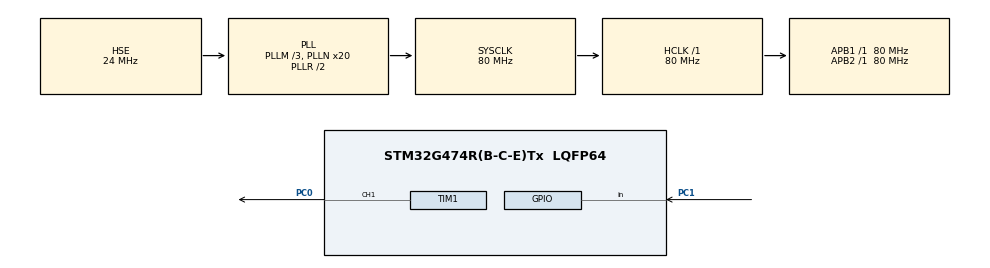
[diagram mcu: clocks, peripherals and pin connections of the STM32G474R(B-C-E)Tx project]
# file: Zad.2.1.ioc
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Dma.Request0=TIM1_CH1
Dma.TIM1_CH1.0.Direction=DMA_MEMORY_TO_PERIPH
Dma.TIM1_CH1.0.EventEnable=DISABLE
Dma.TIM1_CH1.0.Instance=DMA1_Channel1
Dma.TIM1_CH1.0.MemDataAlignment=DMA_MDATAALIGN_BYTE
Dma.TIM1_CH1.0.MemInc=DMA_MINC_ENABLE
Dma.TIM1_CH1.0.Mode=DMA_NORMAL
Dma.TIM1_CH1.0.PeriphDataAlignment=DMA_PDATAALIGN_HALFWORD
Dma.TIM1_CH1.0.PeriphInc=DMA_PINC_DISABLE
Dma.TIM1_CH1.0.Polarity=HAL_DMAMUX_REQ_GEN_RISING
Dma.TIM1_CH1.0.Priority=DMA_PRIORITY_LOW
Dma.TIM1_CH1.0.RequestNumber=1
Dma.TIM1_CH1.0.SignalID=NONE
Dma.TIM1_CH1.0.SyncEnable=DISABLE
Dma.TIM1_CH1.0.SyncPolarity=HAL_DMAMUX_SYNC_NO_EVENT
Dma.TIM1_CH1.0.SyncRequestNumber=1
Dma.TIM1_CH1.0.SyncSignalID=NONE
Mcu.Family=STM32G4
Mcu.Name=STM32G474R(B-C-E)Tx
Mcu.Package=LQFP64
NVIC.DMA1_Channel1_IRQn=true\:0\:0\:false\:false\:true\:false\:true\:true
NVIC.PriorityGroup=NVIC_PRIORITYGROUP_4
PC0.Signal=S_TIM1_CH1
PC1.GPIO_PuPd=GPIO_PULLUP
PC1.Signal=GPIO_Input
PF0-OSC_IN.Mode=HSE-External-Oscillator
PF0-OSC_IN.Signal=RCC_OSC_IN
PF1-OSC_OUT.Mode=HSE-External-Oscillator
PF1-OSC_OUT.Signal=RCC_OSC_OUT
ProjectManager.HeapSize=0x200
ProjectManager.StackSize=0x400
ProjectManager.TargetToolchain=CMake
RCC.ADC12Freq_Value=80000000
RCC.ADC345Freq_Value=80000000
RCC.AHBFreq_Value=80000000
RCC.APB1Freq_Value=80000000
RCC.APB1TimFreq_Value=80000000
RCC.APB2Freq_Value=80000000
RCC.APB2TimFreq_Value=80000000
RCC.CortexFreq_Value=80000000
RCC.EXTERNAL_CLOCK_VALUE=12288000
RCC.HCLKFreq_Value=80000000
RCC.HSE_VALUE=24000000
RCC.HSI48_VALUE=48000000
RCC.HSI_VALUE=16000000
RCC.LSE_VALUE=32768
RCC.PLLM=RCC_PLLM_DIV3
RCC.PLLN=20
RCC.PLLSourceVirtual=RCC_PLLSOURCE_HSE
RCC.SYSCLKFreq_VALUE=80000000
RCC.SYSCLKSource=RCC_SYSCLKSOURCE_PLLCLK
RCC.USBFreq_Value=80000000
RCC.VCOOutputFreq_Value=160000000
SH.S_TIM1_CH1.0=TIM1_CH1,PWM Generation1 CH1
TIM1.Channel-PWM\ Generation1\ CH1=TIM_CHANNEL_1
TIM1.PeriodNoDither=100-1
VP_SYS_VS_DBSignals.Mode=DisableDeadBatterySignals
VP_TIM1_VS_ClockSourceINT.Mode=Internal
board=custom

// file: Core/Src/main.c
/* USER CODE BEGIN Header */
/**
  ******************************************************************************
  * @file           : main.c
  * @brief          : Main program body
  ******************************************************************************
  * @attention
  *
  * Copyright (c) 2026 STMicroelectronics.
  * All rights reserved.
  *
  * This software is licensed under terms that can be found in the LICENSE file
  * in the root directory of this software component.
  * If no LICENSE file comes with this software, it is provided AS-IS.
  *
  ******************************************************************************
  */
/* USER CODE END Header */
#include "main.h"

/* USER CODE BEGIN Includes */
#include "driver-ws2812.h"
/* USER CODE END Includes */

/* USER CODE BEGIN PD */
#define BTN_GPIO 	 GPIOC
#define BTN_PIN  	 GPIO_PIN_1
#define BTN_DEBOUNCE 50 // in ms
/* USER CODE END PD */

TIM_HandleTypeDef htim1;
DMA_HandleTypeDef hdma_tim1_ch1;

void SystemClock_Config(void);
static void MX_GPIO_Init(void);
static void MX_DMA_Init(void);
static void MX_TIM1_Init(void);

/* USER CODE BEGIN 0 */
void HAL_TIM_PWM_PulseFinishedCallback(TIM_HandleTypeDef *htim) {
	WS2812_FinishedCallback();
}
/* USER CODE END 0 */

int main(void)
{

  /* MCU Configuration--------------------------------------------------------*/

  /* Reset of all peripherals, Initializes the Flash interface and the Systick. */
  HAL_Init();

  /* Configure the system clock */
  SystemClock_Config();

  /* Initialize all configured peripherals */
  MX_GPIO_Init();
  MX_DMA_Init();
  MX_TIM1_Init();
  /* USER CODE BEGIN 2 */
  WS2812_Init();

  uint8_t b_pulses = 0, btn_prev = 1;
  uint8_t r_brightness = 0, g_brightness = 0, b_brightness = 0;
  uint32_t r_tick = 0, g_tick = 0, b_tick = 0, btn_tick = 0;
  /* USER CODE END 2 */

  /* Infinite loop */
  while (1)
  {

    /* USER CODE BEGIN 3 */
	/*
	 * Button handling
	 * To minimize external components needed we are using
	 * an internal pullup and software debouncing
	 * */
	if(!HAL_GPIO_ReadPin(BTN_GPIO, BTN_PIN) & (btn_prev == 1) &
		((HAL_GetTick() - btn_tick) >= BTN_DEBOUNCE)) {
	  btn_tick = HAL_GetTick();
	  btn_prev = 0;

	  b_pulses = 3;
	  b_tick = 0;
	} else if(HAL_GPIO_ReadPin(BTN_GPIO, BTN_PIN) &
	  	((HAL_GetTick() - btn_tick) >= BTN_DEBOUNCE)) {
	  btn_tick = HAL_GetTick();
	  btn_prev = 1;
	}

	/*
	 * Red - 50% duty cycle square wave
	 * */
	if(HAL_GetTick() - r_tick >= 1500) {
	  r_tick = HAL_GetTick();

	  r_brightness = r_brightness==0 ? 255 : 0;
	}

	/*
	 * Green - sawtooth
	 * 3000ms period / 256 values is roughly 11.7ms per step
	 * We need to round it to 12, so resulting period would be 3072ms
	 * We can get closer to 3s if we count only to 249 ((249+1)*12ms=3000ms)
	 * */
	if(HAL_GetTick() - g_tick >= 12) {
	  g_tick = HAL_GetTick();

	  g_brightness++;

	  if(g_brightness >= 250) {
		g_brightness = 0;
	  }
	}

	/*
	 * Blue - 3 pulses after clicking a button
	 * */
	if((b_pulses > 0) & (HAL_GetTick() - b_tick >= 500)) {
	  b_tick = HAL_GetTick();

	  if(b_brightness == 0) {
	  	b_brightness = 255;
	  } else {
	  	b_brightness = 0;
	  	b_pulses--;
	  }
	}

	WS2812_SetLED(0, r_brightness, g_brightness, b_brightness);
	WS2812_Update();
  }
  /* USER CODE END 3 */
}

void SystemClock_Config(void)
{
  RCC_OscInitTypeDef RCC_OscInitStruct = {0};
  RCC_ClkInitTypeDef RCC_ClkInitStruct = {0};

  /** Configure the main internal regulator output voltage
  */
  HAL_PWREx_ControlVoltageScaling(PWR_REGULATOR_VOLTAGE_SCALE1);

  /** Initializes the RCC Oscillators according to the specified parameters
  * in the RCC_OscInitTypeDef structure.
  */
  RCC_OscInitStruct.OscillatorType = RCC_OSCILLATORTYPE_HSE;
  RCC_OscInitStruct.HSEState = RCC_HSE_ON;
  RCC_OscInitStruct.PLL.PLLState = RCC_PLL_ON;
  RCC_OscInitStruct.PLL.PLLSource = RCC_PLLSOURCE_HSE;
  RCC_OscInitStruct.PLL.PLLM = RCC_PLLM_DIV3;
  RCC_OscInitStruct.PLL.PLLN = 20;
  RCC_OscInitStruct.PLL.PLLP = RCC_PLLP_DIV2;
  RCC_OscInitStruct.PLL.PLLQ = RCC_PLLQ_DIV2;
  RCC_OscInitStruct.PLL.PLLR = RCC_PLLR_DIV2;
  if (HAL_RCC_OscConfig(&RCC_OscInitStruct) != HAL_OK)
  {
    Error_Handler();
  }

  /** Initializes the CPU, AHB and APB buses clocks
  */
  RCC_ClkInitStruct.ClockType = RCC_CLOCKTYPE_HCLK|RCC_CLOCKTYPE_SYSCLK
                              |RCC_CLOCKTYPE_PCLK1|RCC_CLOCKTYPE_PCLK2;
  RCC_ClkInitStruct.SYSCLKSource = RCC_SYSCLKSOURCE_PLLCLK;
  RCC_ClkInitStruct.AHBCLKDivider = RCC_SYSCLK_DIV1;
  RCC_ClkInitStruct.APB1CLKDivider = RCC_HCLK_DIV1;
  RCC_ClkInitStruct.APB2CLKDivider = RCC_HCLK_DIV1;

  if (HAL_RCC_ClockConfig(&RCC_ClkInitStruct, FLASH_LATENCY_2) != HAL_OK)
  {
    Error_Handler();
  }
}

static void MX_TIM1_Init(void)
{

  TIM_ClockConfigTypeDef sClockSourceConfig = {0};
  TIM_MasterConfigTypeDef sMasterConfig = {0};
  TIM_OC_InitTypeDef sConfigOC = {0};
  TIM_BreakDeadTimeConfigTypeDef sBreakDeadTimeConfig = {0};

  htim1.Instance = TIM1;
  htim1.Init.Prescaler = 0;
  htim1.Init.CounterMode = TIM_COUNTERMODE_UP;
  htim1.Init.Period = 99;
  htim1.Init.ClockDivision = TIM_CLOCKDIVISION_DIV1;
  htim1.Init.RepetitionCounter = 0;
  htim1.Init.AutoReloadPreload = TIM_AUTORELOAD_PRELOAD_DISABLE;
  if (HAL_TIM_Base_Init(&htim1) != HAL_OK)
  {
    Error_Handler();
  }
  sClockSourceConfig.ClockSource = TIM_CLOCKSOURCE_INTERNAL;
  if (HAL_TIM_ConfigClockSource(&htim1, &sClockSourceConfig) != HAL_OK)
  {
    Error_Handler();
  }
  if (HAL_TIM_PWM_Init(&htim1) != HAL_OK)
  {
    Error_Handler();
  }
  sMasterConfig.MasterOutputTrigger = TIM_TRGO_RESET;
  sMasterConfig.MasterOutputTrigger2 = TIM_TRGO2_RESET;
  sMasterConfig.MasterSlaveMode = TIM_MASTERSLAVEMODE_DISABLE;
  if (HAL_TIMEx_MasterConfigSynchronization(&htim1, &sMasterConfig) != HAL_OK)
  {
    Error_Handler();
  }
  sConfigOC.OCMode = TIM_OCMODE_PWM1;
  sConfigOC.Pulse = 0;
  sConfigOC.OCPolarity = TIM_OCPOLARITY_HIGH;
  sConfigOC.OCNPolarity = TIM_OCNPOLARITY_HIGH;
  sConfigOC.OCFastMode = TIM_OCFAST_DISABLE;
  sConfigOC.OCIdleState = TIM_OCIDLESTATE_RESET;
  sConfigOC.OCNIdleState = TIM_OCNIDLESTATE_RESET;
  if (HAL_TIM_PWM_ConfigChannel(&htim1, &sConfigOC, TIM_CHANNEL_1) != HAL_OK)
  {
    Error_Handler();
  }
  sBreakDeadTimeConfig.OffStateRunMode = TIM_OSSR_DISABLE;
  sBreakDeadTimeConfig.OffStateIDLEMode = TIM_OSSI_DISABLE;
  sBreakDeadTimeConfig.LockLevel = TIM_LOCKLEVEL_OFF;
  sBreakDeadTimeConfig.DeadTime = 0;
  sBreakDeadTimeConfig.BreakState = TIM_BREAK_DISABLE;
  sBreakDeadTimeConfig.BreakPolarity = TIM_BREAKPOLARITY_HIGH;
  sBreakDeadTimeConfig.BreakFilter = 0;
  sBreakDeadTimeConfig.BreakAFMode = TIM_BREAK_AFMODE_INPUT;
  sBreakDeadTimeConfig.Break2State = TIM_BREAK2_DISABLE;
  sBreakDeadTimeConfig.Break2Polarity = TIM_BREAK2POLARITY_HIGH;
  sBreakDeadTimeConfig.Break2Filter = 0;
  sBreakDeadTimeConfig.Break2AFMode = TIM_BREAK_AFMODE_INPUT;
  sBreakDeadTimeConfig.AutomaticOutput = TIM_AUTOMATICOUTPUT_DISABLE;
  if (HAL_TIMEx_ConfigBreakDeadTime(&htim1, &sBreakDeadTimeConfig) != HAL_OK)
  {
    Error_Handler();
  }
  HAL_TIM_MspPostInit(&htim1);

}

static void MX_DMA_Init(void)
{

  /* DMA controller clock enable */
  __HAL_RCC_DMAMUX1_CLK_ENABLE();
  __HAL_RCC_DMA1_CLK_ENABLE();

  /* DMA interrupt init */
  /* DMA1_Channel1_IRQn interrupt configuration */
  HAL_NVIC_SetPriority(DMA1_Channel1_IRQn, 0, 0);
  HAL_NVIC_EnableIRQ(DMA1_Channel1_IRQn);

}

static void MX_GPIO_Init(void)
{
  GPIO_InitTypeDef GPIO_InitStruct = {0};

  /* GPIO Ports Clock Enable */
  __HAL_RCC_GPIOF_CLK_ENABLE();
  __HAL_RCC_GPIOC_CLK_ENABLE();

  /*Configure GPIO pin : PC1 */
  GPIO_InitStruct.Pin = GPIO_PIN_1;
  GPIO_InitStruct.Mode = GPIO_MODE_INPUT;
  GPIO_InitStruct.Pull = GPIO_PULLUP;
  HAL_GPIO_Init(GPIOC, &GPIO_InitStruct);

}

void Error_Handler(void)
{
  __disable_irq();
  while (1)
  {
  }
}
